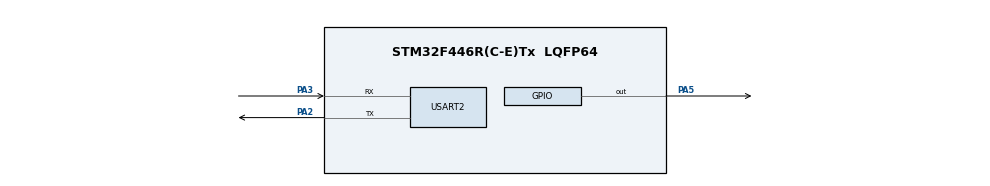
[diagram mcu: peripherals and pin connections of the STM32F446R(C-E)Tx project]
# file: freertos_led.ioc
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FREERTOS.Tasks01=defaultTask,24,128,StartDefaultTask,Default,NULL,Dynamic,NULL,NULL;LED_Task,8,128,StartLEDTask,Default,NULL,Dynamic,NULL,NULL;UART_Task,24,128,StartUARTTask,Default,NULL,Dynamic,NULL,NULL
Mcu.Family=STM32F4
Mcu.Name=STM32F446R(C-E)Tx
Mcu.Package=LQFP64
NVIC.PriorityGroup=NVIC_PRIORITYGROUP_4
NVIC.TIM6_DAC_IRQn=true\:15\:0\:false\:false\:true\:false\:false\:true\:true
NVIC.TimeBase=TIM6_DAC_IRQn
NVIC.TimeBaseIP=TIM6
PA13.Mode=Serial_Wire
PA13.Signal=SYS_JTMS-SWDIO
PA14.Mode=Serial_Wire
PA14.Signal=SYS_JTCK-SWCLK
PA2.Mode=Asynchronous
PA2.Signal=USART2_TX
PA3.Mode=Asynchronous
PA3.Signal=USART2_RX
PA5.Signal=GPIO_Output
ProjectManager.HeapSize=0x200
ProjectManager.StackSize=0x400
ProjectManager.TargetToolchain=STM32CubeIDE
RCC.CortexFreq_Value=16000000
RCC.USBFreq_Value=96000000
RCC.VCOOutputFreq_Value=192000000
USART2.VirtualMode=VM_ASYNC
VP_FREERTOS_VS_CMSIS_V2.Mode=CMSIS_V2
VP_SYS_VS_tim6.Mode=TIM6
board=custom

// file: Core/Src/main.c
/* USER CODE BEGIN Header */
/**
  ******************************************************************************
  * @file           : main.c
  * @brief          : Main program body
  ******************************************************************************
  * @attention
  *
  * Copyright (c) 2026 STMicroelectronics.
  * All rights reserved.
  *
  * This software is licensed under terms that can be found in the LICENSE file
  * in the root directory of this software component.
  * If no LICENSE file comes with this software, it is provided AS-IS.
  *
  ******************************************************************************
  */
/* USER CODE END Header */
#include "main.h"
#include "cmsis_os.h"
#include "usart.h"
#include "gpio.h"

void SystemClock_Config(void);
void MX_FREERTOS_Init(void);

int main(void)
{

  /* MCU Configuration--------------------------------------------------------*/

  /* Reset of all peripherals, Initializes the Flash interface and the Systick. */
  HAL_Init();

  /* Configure the system clock */
  SystemClock_Config();

  /* Initialize all configured peripherals */
  MX_GPIO_Init();
  MX_USART2_UART_Init();

  /* Init scheduler */
  osKernelInitialize();  /* Call init function for freertos objects (in cmsis_os2.c) */
  MX_FREERTOS_Init();

  /* Start scheduler */
  osKernelStart();

  /* We should never get here as control is now taken by the scheduler */

  /* Infinite loop */
  while (1)
  {

  }
}

void SystemClock_Config(void)
{
  RCC_OscInitTypeDef RCC_OscInitStruct = {0};
  RCC_ClkInitTypeDef RCC_ClkInitStruct = {0};

  /** Configure the main internal regulator output voltage
  */
  __HAL_RCC_PWR_CLK_ENABLE();
  __HAL_PWR_VOLTAGESCALING_CONFIG(PWR_REGULATOR_VOLTAGE_SCALE3);

  /** Initializes the RCC Oscillators according to the specified parameters
  * in the RCC_OscInitTypeDef structure.
  */
  RCC_OscInitStruct.OscillatorType = RCC_OSCILLATORTYPE_HSI;
  RCC_OscInitStruct.HSIState = RCC_HSI_ON;
  RCC_OscInitStruct.HSICalibrationValue = RCC_HSICALIBRATION_DEFAULT;
  RCC_OscInitStruct.PLL.PLLState = RCC_PLL_NONE;
  if (HAL_RCC_OscConfig(&RCC_OscInitStruct) != HAL_OK)
  {
    Error_Handler();
  }

  /** Initializes the CPU, AHB and APB buses clocks
  */
  RCC_ClkInitStruct.ClockType = RCC_CLOCKTYPE_HCLK|RCC_CLOCKTYPE_SYSCLK
                              |RCC_CLOCKTYPE_PCLK1|RCC_CLOCKTYPE_PCLK2;
  RCC_ClkInitStruct.SYSCLKSource = RCC_SYSCLKSOURCE_HSI;
  RCC_ClkInitStruct.AHBCLKDivider = RCC_SYSCLK_DIV1;
  RCC_ClkInitStruct.APB1CLKDivider = RCC_HCLK_DIV1;
  RCC_ClkInitStruct.APB2CLKDivider = RCC_HCLK_DIV1;

  if (HAL_RCC_ClockConfig(&RCC_ClkInitStruct, FLASH_LATENCY_0) != HAL_OK)
  {
    Error_Handler();
  }
}

void HAL_TIM_PeriodElapsedCallback(TIM_HandleTypeDef *htim)
{
  if (htim->Instance == TIM6)
  {
    HAL_IncTick();
  }
}

void Error_Handler(void)
{
  __disable_irq();
  while (1)
  {
  }
}

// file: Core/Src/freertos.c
/* USER CODE BEGIN Header */
/**
  ******************************************************************************
  * File Name          : freertos.c
  * Description        : Code for freertos applications
  ******************************************************************************
  * @attention
  *
  * Copyright (c) 2026 STMicroelectronics.
  * All rights reserved.
  *
  * This software is licensed under terms that can be found in the LICENSE file
  * in the root directory of this software component.
  * If no LICENSE file comes with this software, it is provided AS-IS.
  *
  ******************************************************************************
  */
/* USER CODE END Header */

#include "FreeRTOS.h"
#include "task.h"
#include "main.h"
#include "cmsis_os.h"

/* USER CODE BEGIN Includes */
extern UART_HandleTypeDef huart2;
/* USER CODE END Includes */

/* Definitions for defaultTask */
osThreadId_t defaultTaskHandle;
const osThreadAttr_t defaultTask_attributes = {
  .name = "defaultTask",
  .stack_size = 128 * 4,
  .priority = (osPriority_t) osPriorityNormal,
};
/* Definitions for LED_Task */
osThreadId_t LED_TaskHandle;
const osThreadAttr_t LED_Task_attributes = {
  .name = "LED_Task",
  .stack_size = 128 * 4,
  .priority = (osPriority_t) osPriorityLow,
};
/* Definitions for UART_Task */
osThreadId_t UART_TaskHandle;
const osThreadAttr_t UART_Task_attributes = {
  .name = "UART_Task",
  .stack_size = 128 * 4,
  .priority = (osPriority_t) osPriorityNormal,
};

void StartDefaultTask(void *argument);
void StartLEDTask(void *argument);
void StartUARTTask(void *argument);

void MX_FREERTOS_Init(void); /* (MISRA C 2004 rule 8.1) */

void MX_FREERTOS_Init(void) {

  /* Create the thread(s) */
  /* creation of defaultTask */
  defaultTaskHandle = osThreadNew(StartDefaultTask, NULL, &defaultTask_attributes);

  /* creation of LED_Task */
  LED_TaskHandle = osThreadNew(StartLEDTask, NULL, &LED_Task_attributes);

  /* creation of UART_Task */
  UART_TaskHandle = osThreadNew(StartUARTTask, NULL, &UART_Task_attributes);

}

void StartDefaultTask(void *argument)
{
  for(;;)
  {
    osDelay(1);
  }
}

void StartLEDTask(void *argument)
{
  /* USER CODE BEGIN StartLEDTask */
  for(;;)
  {
    HAL_GPIO_TogglePin(GPIOA, GPIO_PIN_5);
    osDelay(500);
  }
  /* USER CODE END StartLEDTask */
}

void StartUARTTask(void *argument)
{
  /* USER CODE BEGIN StartUARTTask */
  char msg[] = "Hello from UART Task!\r\n";
  for(;;)
  {
    HAL_UART_Transmit(&huart2, (uint8_t*)msg, sizeof(msg)-1, 100);
    osDelay(1000);
  }
  /* USER CODE END StartUARTTask */
}
